AUTOSAR XML (schema 00048)
package /ComponentTypes
  swc implementation ComEx_Implementation: behavior=ComEx_InternalBehavior
    code-descriptors:
      code Default: artifact-descriptors=autosar-engineering-object=category=SWSRC
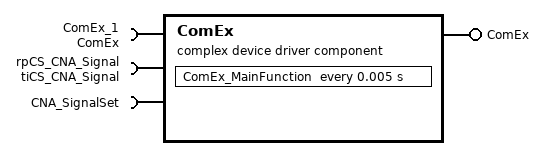
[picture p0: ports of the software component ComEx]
  complex device driver sw component type ComEx
    provide port ComEx: provided-interface=ComEx
      provided-com-specs:
        operation=GetRxE2EStatus, queue-length=1
        operation=ReceiveSignal, queue-length=1
        operation=SendSignal, queue-length=1
    require port ComEx_1: required-com-specs=[GetRxE2EStatus, ReceiveSignal, SendSignal], required-interface=ComEx
    require port rpCS_CNA_Signal: client-com-spec=CallBack, required-interface=tiCS_CNA_Signal
    require port CNA_SignalSet: client-com-spec=Operation, required-interface=CNA_SignalSet
    behavior ComEx_InternalBehavior: port-api-option{enable-take-address=true, error-handling=NO-TRANSFORMER-ERROR-HANDLING, indirect-api=false, port=rpCS_CNA_Signal}
      exclusive area ExclusiveArea_ComEx
      operation invoked event OIT_ComEx_GetRxE2EStatus_ComEx_GetRxE2EStatus: start-on-event=ComEx_GetRxE2EStatus, operation=ComEx.GetRxE2EStatus
      init event ComEx_InitEvent: start-on-event=ComEx_Init
      timing event TMT_ComEx_MainFunction: start-on-event=ComEx_MainFunction, period=0.005
      operation invoked event OIT_ComEx_ReceiveSignal_ComEx_ReceiveSignal: start-on-event=ComEx_ReceiveSignal, operation=ComEx.ReceiveSignal
      operation invoked event OIT_ComEx_SendSignal_ComEx_SendSignal: start-on-event=ComEx_SendSignal, operation=ComEx.SendSignal
      5 x runnable:
        ComEx_GetRxE2EStatus
        ComEx_Init
        ComEx_MainFunction
          4 x sync call:
            SC_ComEx_1_GetRxE2EStatus: operation=ComEx_1.GetRxE2EStatus
            SC_ComEx_1_ReceiveSignal: operation=ComEx_1.ReceiveSignal
            SC_ComEx_1_SendSignal: operation=ComEx_1.SendSignal
            SC_rpCS_CNA_Signal_CallBack: operation=rpCS_CNA_Signal.CallBack
        ComEx_ReceiveSignal: can-enter-exclusive-area=ExclusiveArea_ComEx, can-be-invoked-concurrently=true
        ComEx_SendSignal: can-be-invoked-concurrently=true
          sync call SC_CNA_SignalSet_Operation: operation=CNA_SignalSet.Operation
